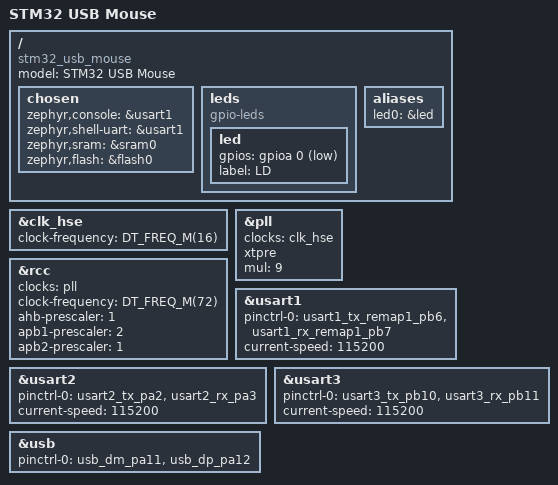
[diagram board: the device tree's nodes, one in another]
/*
 * Copyright (c) 2019, embedjournal.com
 *
 * SPDX-License-Identifier: Apache-2.0
 */

/dts-v1/;
#include <st/f1/stm32f103X8.dtsi>
#include <st/f1/stm32f103c(8-b)tx-pinctrl.dtsi>

/ {
	model = "STM32 USB Mouse";
	compatible = "stm32_usb_mouse", "st,stm32f103c8";

	chosen {
		zephyr,console = &usart1;
		zephyr,shell-uart = &usart1;
		zephyr,sram = &sram0;
		zephyr,flash = &flash0;
	};

	leds {
		compatible = "gpio-leds";

		/* Unused pin, for compatibility with samples */
		led: led {
			gpios = <&gpioa 0 GPIO_ACTIVE_LOW>;
			label = "LD";
		};
	};

	aliases {
		led0 = &led;
	};
};

&clk_hse {
	clock-frequency = <DT_FREQ_M(16)>;
	status = "okay";
};

&pll {
	clocks = <&clk_hse>;
	xtpre;
	mul = <9>;
	/* usbpre not set: USB clock = 72 / 1.5: 48MHz */
	status = "okay";
};

&rcc {
	clocks = <&pll>;
	clock-frequency = <DT_FREQ_M(72)>;
	ahb-prescaler = <1>;
	apb1-prescaler = <2>;
	apb2-prescaler = <1>;
};

&usart1 {
	pinctrl-0 = <&usart1_tx_remap1_pb6 &usart1_rx_remap1_pb7>;
	current-speed = <115200>;
	pinctrl-names = "default";
	status = "okay";
};

&usart2 {
	pinctrl-0 = <&usart2_tx_pa2 &usart2_rx_pa3>;
	current-speed = <115200>;
	pinctrl-names = "default";
	status = "okay";
};

&usart3 {
	pinctrl-0 = <&usart3_tx_pb10 &usart3_rx_pb11>;
	current-speed = <115200>;
	pinctrl-names = "default";
	status = "okay";
};

zephyr_udc0: &usb {
	pinctrl-0 = <&usb_dm_pa11 &usb_dp_pa12>;
	pinctrl-names = "default";
	status = "okay";
};
